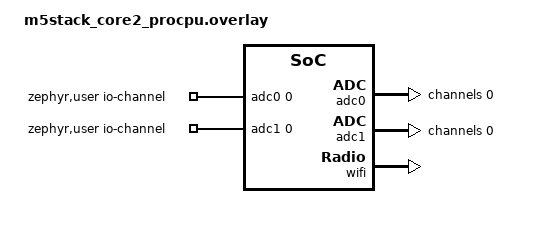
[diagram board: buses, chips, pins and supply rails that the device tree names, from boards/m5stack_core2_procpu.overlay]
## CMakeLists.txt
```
# SPDX-License-Identifier: Apache-2.0
cmake_minimum_required(VERSION 3.20.0)

set(BOARD m5stack_core2/esp32/procpu)
set(CONF_FILE prj.conf overlay-wifi.conf)

find_package(Zephyr REQUIRED HINTS $ENV{ZEPHYR_BASE})
project(weather_station)

target_include_directories(app PRIVATE include)

target_sources(app PRIVATE 
    src/wifi.c
    src/sockets.c
    src/weather_station.c
    src/main.c
)
target_sources_ifdef(CONFIG_WIFI app PRIVATE src/wifi.c)

set(gen_dir ${ZEPHYR_BINARY_DIR}/include/generated/)

generate_inc_file_for_target(
    app
    src/globalsign_r1.der
    ${gen_dir}/globalsign_r1.der.inc
    )
```

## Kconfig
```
#  Copyright (c) 2020 Gerson Fernando Budke <nandojve@gmail.com>
#  SPDX-License-Identifier: Apache-2.0

mainmenu "CSSE4011 Weather Station HTTP Client Configuration"

menu "Weather Station HTTP Client Configuration"

config HTTP_WIFI_SSID
	string "WIFI SSID - Network name"
	default "my_network"

config HTTP_WIFI_PSK
	string "WIFI PSK - Network password key"
	default "secret_passwd"

endmenu

source "Kconfig.zephyr"
```

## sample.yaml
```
sample:
  name: ADC devicetree driver sample
tests:
  sample.drivers.adc.adc_dt:
    tags:
      - adc
    depends_on: adc
    platform_allow:
      - m5stack_core2/esp32/procpu
    harness: console
    timeout: 10
    harness_config:
      type: multi_line
      regex:
        - "ADC reading\\[\\d+\\]:"
        - "- .+, channel \\d+: -?\\d+"
```

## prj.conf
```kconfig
CONFIG_ESP32_USE_UNSUPPORTED_REVISION=y
# ADC
CONFIG_ADC=y
CONFIG_SHELL=y
CONFIG_GPIO=y
CONFIG_GPIO_ESP32=y

CONFIG_CBPRINTF_FP_SUPPORT=y

# App stack
CONFIG_MAIN_STACK_SIZE=4096

### WiFi Connectivity ###
# C Library
# Default use minimal libc and with COMMON_LIBC_MALLOC_ARENA_SIZE defining
# HEAP size (512 bytes) are enough to run DNS.
CONFIG_COMMON_LIBC_MALLOC_ARENA_SIZE=4096

CONFIG_POSIX_API=y

# Networking config
CONFIG_NETWORKING=y
CONFIG_NET_IPV4=y
CONFIG_NET_IPV6=n
CONFIG_NET_TCP=y
CONFIG_NET_SHELL=y

# Sockets
CONFIG_NET_SOCKETS=y
CONFIG_ZVFS_POLL_MAX=4

# Network driver config
CONFIG_TEST_RANDOM_GENERATOR=y

# Network address config
CONFIG_NET_CONFIG_SETTINGS=y
CONFIG_NET_CONFIG_NEED_IPV4=y
CONFIG_NET_DHCPV4=y

# Resolver
CONFIG_DNS_RESOLVER=y

# HTTP
CONFIG_HTTP_CLIENT=y

# Network debug config
CONFIG_LOG=y
CONFIG_NET_LOG=y
CONFIG_NET_SOCKETS_LOG_LEVEL_DBG=n
CONFIG_NET_HTTP_LOG_LEVEL_DBG=n

# ESP-Specific Configs
CONFIG_WIFI_ESP32=y
CONFIG_NET_L2_ETHERNET=y
```

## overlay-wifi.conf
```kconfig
CONFIG_WIFI=y
CONFIG_HTTP_WIFI_SSID="OPPO Reno12 F 5G"
CONFIG_HTTP_WIFI_PSK="12345678"
CONFIG_NET_SOCKETS_SOCKOPT_TLS=n
CONFIG_NET_SOCKETS=y
CONFIG_MBEDTLS=y
```

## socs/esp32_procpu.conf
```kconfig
CONFIG_WIFI=y

CONFIG_NETWORKING=y
CONFIG_NET_L2_ETHERNET=y

CONFIG_NET_IPV6=n
CONFIG_NET_IPV4=y
CONFIG_NET_DHCPV4=y
CONFIG_ESP32_WIFI_STA_AUTO_DHCPV4=y

CONFIG_NET_LOG=y

CONFIG_HTTP_CLIENT=y
# CONFIG_HTTP_SERVER is not set
```

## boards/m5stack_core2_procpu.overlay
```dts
/ {
	zephyr,user {
		io-channels =
			<&adc0 0>,
			<&adc1 0>;
	};
};

&adc0 {
	status = "okay";
	#address-cells = <1>;
	#size-cells = <0>;

	channel@0 {
		reg = <0>;
		zephyr,gain = "ADC_GAIN_1_4";
		zephyr,reference = "ADC_REF_INTERNAL";
		zephyr,acquisition-time = <ADC_ACQ_TIME_DEFAULT>;
		zephyr,resolution = <12>;
	};
};

&adc1 {
	status = "okay";
	#address-cells = <1>;
	#size-cells = <0>;

	channel@0 {
		reg = <0>;
		zephyr,gain = "ADC_GAIN_1_4";
		zephyr,reference = "ADC_REF_INTERNAL";
		zephyr,acquisition-time = <ADC_ACQ_TIME_DEFAULT>;
		zephyr,resolution = <12>;
	};
};

&gpio0 {
    status = "okay";
};

&wifi {
	status = "okay";
};
```

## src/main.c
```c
/**
 * @file main.c
 * @brief HTTP Client demo application for weather station.
 *
 * This application collects data from a weather station, and sends it to 
 * csse4011-iot.uqcloud.net via an HTTP client. It logs HTTP responses and sensor data.
 */
#include <zephyr/logging/log.h>
#include <zephyr/kernel.h>
#include <zephyr/device.h>
#include <zephyr/drivers/gpio.h>
#include <zephyr/devicetree.h>
#include <zephyr/shell/shell.h>
#include <zephyr/sys/printk.h>
#include <zephyr/net/socket.h>
#include <zephyr/net/http/client.h>
#include <zephyr/random/random.h>
#include <stdio.h>

LOG_MODULE_REGISTER(main);

#include "wifi.h"
#include "sockets.h"
#include "weather_station.h"

#define GPIO_0   DT_NODELABEL(gpio0)
#define GPIO_PIN 27

/* Get device instances */
const struct device *gpio_dev = DEVICE_DT_GET(GPIO_0);
const struct device *adc_dev = DEVICE_DT_GET(DT_NODELABEL(adc0));

/* Global weather station instance */
WeatherStation ws;


/**
 * @brief Cycle Executive.
 *
 * Initializes the ADC and weather station, connects to Wi-Fi, and enters the main loop,
 * periodically collecting sensor data and transmitting it to csse4011-iot.uqcloud.net server.
 *
 * @return Always returns 0.
 */
int main(void)
{
    printk("Starting program\n");

    /* Initialize WiFi and weather station */
	wifi_connect();
    weather_station_init(&ws, adc_dev, gpio_dev, GPIO_PIN);
    LOG_INF("Weather station initialised\n");

    /* Main loop */
    while (1) {
        float wind_speed = weather_station_get_wind_speed(&ws);
        float wind_direction = weather_station_get_wind_direction(&ws);
        printk("Wind Speed: %f, Wind Direction: %f\n", (double)wind_speed, (double)wind_direction);
        if (http_get_dynamic(wind_speed, wind_direction) < 0) {
            LOG_INF("Error sending GET request.");
        }

        k_msleep(1000);
    }
    return 0;
}
```

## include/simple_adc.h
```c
#ifndef __SIMPLE_ADC_H__
#define __SIMPLE_ADC_H__

#include <stdbool.h>
#include <stdint.h>


/**
 * @brief Initializes the ADC channel.
 *
 * This function configures the ADC channel specified in the device tree overlay.
 * It first checks whether the ADC controller device is ready, and then sets up the ADC channel.
 *
 * @return 0 on success, or a negative error code if initialization fails.
 */
int adc_channel_initialise();

/**
 * @brief Reads the ADC channel and converts the raw value to millivolts.
 *
 * This function performs an ADC read operation on the specified channel.
 * It stores the raw ADC value, interprets it (as a signed value if using differential mode),
 * and converts it into millivolts. The resulting value is stored in the location provided.
 *
 * @param[out] out_val_mv Pointer to an integer where the resulting millivolt value will be stored.
 *
 * @return true if the read and conversion are successful, false otherwise.
 */
bool adc_channel_read_millivolt(int32_t *out_val_mv);

#endif
```

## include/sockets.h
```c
/*
 * Copyright (c) 2020 Gerson Fernando Budke <nandojve@gmail.com>
 *
 * SPDX-License-Identifier: Apache-2.0
 */
 
/**
 * @brief Sends an HTTP GET request with dynamic URL parameters.
 *
 * Constructs a URL using the given wind speed and wind direction, resolves the server address,
 * establishes a connection (with TLS if enabled), sends the HTTP GET request, and then closes the connection.
 *
 * @param wind_speed    The measured wind speed.
 * @param wind_direction The measured wind direction.
 *
 * @return int Returns 0 on success or a negative error code on failure.
 */
int http_get_dynamic(float wind_speed, float wind_direction);
```

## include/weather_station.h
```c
/**
 * @file weather_station.h
 * @brief Weather station sensor driver.
 *
 * Adapted from https://github.com/sparkfun/SparkFun_Weather_Meter_Kit_Arduino_Library
 */

#ifndef SFE_WEATHER_METER_KIT_H
#define SFE_WEATHER_METER_KIT_H

#include <zephyr/drivers/adc.h>
#include <zephyr/drivers/gpio.h>
#include <stdint.h>

#ifdef __cplusplus
extern "C" {
#endif

/*----------------------------------------------------------------------------
 * Macros and Constants
 *----------------------------------------------------------------------------
 * Define the number of wind vane positions, ADC resolution, and conversion
 * constants. Adjust these values as needed.
 */
#define WMK_NUM_ANGLES                 16

#define WMK_ANGLE_0_0                  0
#define WMK_ANGLE_22_5                 1
#define WMK_ANGLE_45_0                 2
#define WMK_ANGLE_67_5                 3
#define WMK_ANGLE_90_0                 4
#define WMK_ANGLE_112_5                5
#define WMK_ANGLE_135_0                6
#define WMK_ANGLE_157_5                7
#define WMK_ANGLE_180_0                8
#define WMK_ANGLE_202_5                9
#define WMK_ANGLE_225_0                10
#define WMK_ANGLE_247_5                11
#define WMK_ANGLE_270_0                12
#define WMK_ANGLE_292_5                13
#define WMK_ANGLE_315_0                14
#define WMK_ANGLE_337_5                15

#define SFE_WMK_ADC_RESOLUTION         10   // Example: 10-bit ADC resolution
#define SFE_WIND_VANE_DEGREES_PER_INDEX 22.5f

/*----------------------------------------------------------------------------
 * Data Structures
 *----------------------------------------------------------------------------
 */

/**
 * @brief Calibration parameters for wind measurements.
 *
 * Contains ADC calibration values for the wind vane and measurement
 * parameters for computing wind speed.
 */
typedef struct {
    uint16_t vaneADCValues[WMK_NUM_ANGLES];
    float    kphPerCountPerSec;
    uint32_t windSpeedMeasurementPeriodMillis;
} SFEWeatherMeterKitCalibrationParams;

/**
 * @brief Main structure for the Weather Meter Kit.
 *
 * Holds calibration parameters, measurement counters, timing information,
 * and device/pin configuration for wind speed and wind direction.
 */
typedef struct {
    SFEWeatherMeterKitCalibrationParams calibrationParams;
    uint32_t windCountsPrevious;
    uint32_t windCounts;
    uint32_t lastWindSpeedMillis;
    const struct device *adc_dev;          /**< ADC device for wind direction sensor */
    int                   wind_dir_adc_channel; /**< ADC channel for wind direction */
    const struct device *gpio_dev;         /**< GPIO device for wind speed sensor */
    int                   wind_speed_pin;   /**< GPIO pin for wind speed sensor */
    struct gpio_callback  wind_speed_cb;    /**< GPIO callback structure */
} SFEWeatherMeterKit;

/*----------------------------------------------------------------------------
 * Public Function Prototypes
 *----------------------------------------------------------------------------
 */

/**
 * @brief Initialize the Weather Meter Kit structure.
 *
 * Configures device pointers, ADC channel, calibration parameters, and resets
 * counters/timers.
 *
 * @param kit Pointer to a SFEWeatherMeterKit structure.
 * @param adc_dev Pointer to the ADC device (obtained via device_get_binding()).
 * @param wind_dir_adc_channel ADC channel number for the wind direction sensor.
 * @param gpio_dev Pointer to the GPIO device for the wind speed sensor.
 * @param wind_speed_pin GPIO pin number for the wind speed sensor.
 */
void SFEWeatherMeterKit_init(SFEWeatherMeterKit *kit,
                             const struct device *adc_dev,
                             int wind_dir_adc_channel,
                             const struct device *gpio_dev,
                             int wind_speed_pin);

/**
 * @brief Begin sensor operation.
 *
 * Configures the wind speed GPIO pin (with pull-up) and sets up the interrupt
 * callback.
 *
 * @param kit Pointer to a SFEWeatherMeterKit structure.
 * @return 0 on success, negative error code on failure.
 */
int SFEWeatherMeterKit_begin(SFEWeatherMeterKit *kit);

/**
 * @brief Get the current calibration parameters.
 *
 * @param kit Pointer to a SFEWeatherMeterKit structure.
 * @return A SFEWeatherMeterKitCalibrationParams structure.
 */
SFEWeatherMeterKitCalibrationParams SFEWeatherMeterKit_getCalibrationParams(SFEWeatherMeterKit *kit);

/**
 * @brief Set new calibration parameters.
 *
 * @param kit Pointer to a SFEWeatherMeterKit structure.
 * @param params New calibration parameters.
 */
void SFEWeatherMeterKit_setCalibrationParams(SFEWeatherMeterKit *kit,
                                             SFEWeatherMeterKitCalibrationParams params);

/**
 * @brief Adjust the ADC resolution of the calibration values.
 *
 * @param kit Pointer to a SFEWeatherMeterKit structure.
 * @param resolutionBits The desired ADC resolution (in bits).
 */
void SFEWeatherMeterKit_setADCResolutionBits(SFEWeatherMeterKit *kit, uint8_t resolutionBits);

/**
 * @brief Get the wind direction in degrees.
 *
 * Reads the ADC value from the wind vane, compares it to calibration values,
 * and returns the closest matching direction.
 *
 * @param kit Pointer to a SFEWeatherMeterKit structure.
 * @return Wind direction in degrees.
 */
float SFEWeatherMeterKit_getWindDirection(SFEWeatherMeterKit *kit);

/**
 * @brief Get the measured wind speed in kilometers per hour.
 *
 * Computes wind speed based on the counts recorded during the last measurement window.
 *
 * @param kit Pointer to a SFEWeatherMeterKit structure.
 * @return Wind speed in kph.
 */
float SFEWeatherMeterKit_getWindSpeed(SFEWeatherMeterKit *kit);

/**
 * @brief Get the number of wind speed counts.
 *
 * Returns the current count of wind speed pulses in the current measurement window.
 *
 * @param kit Pointer to a SFEWeatherMeterKit structure.
 * @return Wind speed counts.
 */
uint32_t SFEWeatherMeterKit_getWindSpeedCounts(SFEWeatherMeterKit *kit);

/**
 * @brief Reset the wind speed measurement filter.
 *
 * Resets wind speed counters and timer to start a new measurement window.
 *
 * @param kit Pointer to a SFEWeatherMeterKit structure.
 */
void SFEWeatherMeterKit_resetWindSpeedFilter(SFEWeatherMeterKit *kit);

/**
 * @brief Generic wrapper for the weather station.
 *
 * This structure encapsulates your SFEWeatherMeterKit instance.
 */
 typedef struct {
    SFEWeatherMeterKit kit;
} WeatherStation;

/**
 * @brief Initialize the weather station.
 *
 * @param ws Pointer to the WeatherStation instance.
 * @param adc_dev ADC device pointer.
 * @param gpio_dev GPIO device pointer.
 * @param gpio_pin The GPIO pin number used.
 */
void weather_station_init(WeatherStation *ws,
                          const struct device *adc_dev,
                          const struct device *gpio_dev,
                          uint32_t gpio_pin);

/**
 * @brief Get the current wind speed.
 *
 * @param ws Pointer to the WeatherStation instance.
 * @return Wind speed as a float.
 */
float weather_station_get_wind_speed(WeatherStation *ws);

/**
 * @brief Get the current wind direction.
 *
 * @param ws Pointer to the WeatherStation instance.
 * @return Wind direction as a float.
 */
float weather_station_get_wind_direction(WeatherStation *ws);

#ifdef __cplusplus
}
#endif

#endif /* SFE_WEATHER_METER_KIT_H */
```

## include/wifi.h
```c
/*
 * Copyright (c) 2020 Gerson Fernando Budke <nandojve@gmail.com>
 *
 * SPDX-License-Identifier: Apache-2.0
 */

#if defined(CONFIG_WIFI)
/**
 * @brief Connect to a WiFi network.
 *
 * Initiates a connection to a WiFi network using the configuration parameters (SSID and PSK)
 * defined in the build configuration.
 */
void wifi_connect(void);

#else
#define wifi_connect()
#endif
```

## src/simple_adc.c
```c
/*
 * Copyright (c) 2020 Libre Solar Technologies GmbH
 *
 * SPDX-License-Identifier: Apache-2.0
 */

#include <inttypes.h>
#include <stddef.h>
#include <stdint.h>

#include <zephyr/device.h>
#include <zephyr/devicetree.h>
#include <zephyr/drivers/adc.h>
#include <zephyr/kernel.h>
#include <zephyr/sys/printk.h>
#include <zephyr/sys/util.h>

#if !DT_NODE_EXISTS(DT_PATH(zephyr_user)) || !DT_NODE_HAS_PROP(DT_PATH(zephyr_user), io_channels)
#error "No suitable devicetree overlay specified"
#endif

/** 
 * ADC channel specification retrieved from the device tree.
 */
static const struct adc_dt_spec adc_channel0 = ADC_DT_SPEC_GET(DT_PATH(zephyr_user));

/**
 * @brief Initializes the ADC channel.
 *
 * This function configures the ADC channel specified in the device tree overlay.
 * It first checks whether the ADC controller device is ready, and then sets up the ADC channel.
 *
 * @return 0 on success, or a negative error code if initialization fails.
 */
int adc_channel_initialise()
{
	/* Configure channels individually prior to sampling. */
	if (!adc_is_ready_dt(&adc_channel0)) {
		printk("ADC controller device %s not ready\n", adc_channel0.dev->name);
		return -ENODEV;
	}

	int err = adc_channel_setup_dt(&adc_channel0);
	if (err < 0) {
		printk("Could not setup channel (%d)\n", err);
		return 0;
	}
	return err;
}

/**
 * @brief Reads the ADC channel and converts the raw value to millivolts.
 *
 * This function performs an ADC read operation on the specified channel.
 * It stores the raw ADC value, interprets it (as a signed value if using differential mode),
 * and converts it into millivolts. The resulting value is stored in the location provided.
 *
 * @param[out] out_val_mv Pointer to an integer where the resulting millivolt value will be stored.
 *
 * @return true if the read and conversion are successful, false otherwise.
 */
bool adc_channel_read_millivolt(int32_t *out_val_mv)
{

	uint16_t buf;
	struct adc_sequence sequence = {
		.buffer = &buf,
		/* buffer size in bytes, not number of samples */
		.buffer_size = sizeof(buf),
	};

	(void)adc_sequence_init_dt(&adc_channel0, &sequence);

	int err = adc_read_dt(&adc_channel0, &sequence);
	if (err < 0) {
		printk("Could not read (%d)\n", err);
		return false;
	}

	/*
	 * If using differential mode, the 16 bit value
	 * in the ADC sample buffer should be a signed 2's
	 * complement value.
	 */
	if (adc_channel0.channel_cfg.differential) {
		*out_val_mv = (int32_t)((int16_t)buf);
	} else {
		*out_val_mv = (int32_t)buf;
	}

	err = adc_raw_to_millivolts_dt(&adc_channel0, out_val_mv);
	/* conversion to mV may not be supported, skip if not */
	if (err < 0) {
		return false;
	}

	return true;
}
```

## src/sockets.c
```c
/*
 * Copyright (c) 2020 Gerson Fernando Budke <nandojve@gmail.com>
 *
 * SPDX-License-Identifier: Apache-2.0
 */

 #include <zephyr/logging/log.h>
 #include <zephyr/net/net_ip.h>
 #include <zephyr/net/socket.h>
 #include <zephyr/net/socketutils.h>
 #include <zephyr/net/dns_resolve.h>
 #include <zephyr/net/tls_credentials.h>
 #include <zephyr/net/http/client.h>
 
 #if defined(CONFIG_NET_SOCKETS_SOCKOPT_TLS)
 #include <zephyr/net/tls_credentials.h>
 #include "ca_certificate.h"
 #endif

 #include "sockets.h"
 
#define HTTP_HOST "csse4011-iot.uqcloud.net"
#define HTTP_PATH "/"
#if defined(CONFIG_NET_SOCKETS_SOCKOPT_TLS)
#define HTTP_PORT "443"
#else
#define HTTP_PORT "80"
#endif

/**
 * @brief Sends an HTTP GET request with a dynamic URL.
 *
 * This function constructs a dynamic URL using the provided wind speed and wind direction values,
 * resolves the server hostname, and establishes a connection (with TLS if configured). It then
 * sends an HTTP GET request to the server with the URL parameters and closes the socket.
 *
 * @param wind_speed    The measured wind speed.
 * @param wind_direction The measured wind direction.
 *
 * @return int Returns 0 on success, or a negative error code on failure.
 */
int http_get_dynamic(float wind_speed, float wind_direction)
{
    int ret;
    struct addrinfo hints = {0}, *res = NULL;
    int sock;

    /* Build the dynamic URL */
    char dynamic_path[100];
    ret = snprintk(dynamic_path, sizeof(dynamic_path),
                   "/add.php?stationid=4011&speed=%.2f&direction=%.2f",
                   (double)wind_speed, (double)wind_direction);
    if (ret <= 0 || ret >= sizeof(dynamic_path)) {
        printk("Error: Could not build dynamic URL.\n");
        return -1;
    }

    printk("Sending GET request to https://%s%s\n", HTTP_HOST, dynamic_path);

    hints.ai_family = AF_INET;
    hints.ai_socktype = SOCK_STREAM;
    ret = getaddrinfo(HTTP_HOST, HTTP_PORT, &hints, &res);
    if (ret != 0) {
        printk("Error: getaddrinfo() failed (%d)\n", ret);
        return -1;
    }

#if defined(CONFIG_NET_SOCKETS_SOCKOPT_TLS)
    sock = socket(res->ai_family, res->ai_socktype, IPPROTO_TLS_1_2);
#else
    sock = socket(res->ai_family, res->ai_socktype, res->ai_protocol);
#endif
    if (sock < 0) {
        printk("Error: socket() failed (%d)\n", sock);
        freeaddrinfo(res);
        return -1;
    }

#if defined(CONFIG_NET_SOCKETS_SOCKOPT_TLS)
    {
        sec_tag_t sec_tag_opt[] = { CA_CERTIFICATE_TAG };
        ret = setsockopt(sock, SOL_TLS, TLS_SEC_TAG_LIST, sec_tag_opt, sizeof(sec_tag_opt));
        if (ret < 0) {
            printk("Error: setsockopt TLS_SEC_TAG_LIST: %d\n", ret);
            close(sock);
            freeaddrinfo(res);
            return ret;
        }
        ret = setsockopt(sock, SOL_TLS, TLS_HOSTNAME, HTTP_HOST, strlen(HTTP_HOST));
        if (ret < 0) {
            printk("Error: setsockopt TLS_HOSTNAME: %d\n", ret);
            close(sock);
            freeaddrinfo(res);
            return ret;
        }
    }
#endif

    ret = connect(sock, res->ai_addr, res->ai_addrlen);
    if (ret < 0) {
        printk("Error: connect() failed (%d)\n", ret);
        close(sock);
        freeaddrinfo(res);
        return ret;
    }
    freeaddrinfo(res);

    /* Build the HTTP GET request with the dynamic URL */
    char req_buf[512];
    int req_len = snprintk(req_buf, sizeof(req_buf),
                           "GET %s HTTP/1.1\r\n"
                           "Host: %s\r\n"
                           "Connection: close\r\n"
                           "\r\n",
                           dynamic_path, HTTP_HOST);
    if (req_len <= 0 || req_len >= sizeof(req_buf)) {
        printk("Error: Request buffer too small or snprintk error\n");
        close(sock);
        return -1;
    }

    ret = send(sock, req_buf, req_len, 0);
    if (ret < 0) {
        printk("Error: send() failed (%d)\n", ret);
        close(sock);
        return ret;
    }

    /* Receive and print the server response */
    // adds latency, by-pass this for now.
    // char response[512];
    // while (1) {
    //     ret = recv(sock, response, sizeof(response) - 1, 0);
    //     if (ret < 0) {
    //         printk("Error: recv() failed (%d)\n", ret);
    //         break;
    //     }
    //     if (ret == 0) {
    //         /* Server closed connection */
    //         break;
    //     }
    //     response[ret] = '\0';
    //     printk("%s", response);
    // }
    close(sock);
    printk("\nSocket closed.\n");
    return 0;
}
```

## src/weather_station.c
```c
/**
 * @file weather_station.c
 * @brief Weather station sensor driver.
 *
 * Adapted from github.com/sparkfun/SparkFun_Weather_Meter_Kit_Arduino_Library
 */

#include <weather_station.h>
#include <zephyr/device.h>
#include <zephyr/sys/printk.h>
#include <stdint.h>
#include <string.h>
#include <stdlib.h>

/*----------------------------------------------------------------------------
 * Macros and Calibration Constants
 *----------------------------------------------------------------------------
 * Define the number of wind vane positions and the calibration ADC values.
 * Adjust these values to suit your hardware and calibration.
 */
#define SFE_WMK_ADC_ANGLE_0_0   444
#define SFE_WMK_ADC_ANGLE_22_5  231
#define SFE_WMK_ADC_ANGLE_45_0  263
#define SFE_WMK_ADC_ANGLE_67_5  52
#define SFE_WMK_ADC_ANGLE_90_0  57
#define SFE_WMK_ADC_ANGLE_112_5 41
#define SFE_WMK_ADC_ANGLE_135_0 107
#define SFE_WMK_ADC_ANGLE_157_5 75
#define SFE_WMK_ADC_ANGLE_180_0 164
#define SFE_WMK_ADC_ANGLE_202_5 142
#define SFE_WMK_ADC_ANGLE_225_0 358
#define SFE_WMK_ADC_ANGLE_247_5 340
#define SFE_WMK_ADC_ANGLE_270_0 531
#define SFE_WMK_ADC_ANGLE_292_5 466
#define SFE_WMK_ADC_ANGLE_315_0 500
#define SFE_WMK_ADC_ANGLE_337_5 398 

#define SFE_WMK_ADC_RESOLUTION          10  // 10-bit ADC resolution
#define SFE_WIND_VANE_DEGREES_PER_INDEX 22.5f

/*----------------------------------------------------------------------------
 * Global Instance Pointer for Interrupt Context
 *----------------------------------------------------------------------------
 * For simplicity (and because typical ISRs cannot have a context pointer),
 * we use a global pointer to the one active kit instance.
 */
static SFEWeatherMeterKit *kit_instance = NULL;

/*----------------------------------------------------------------------------
 * Forward Declarations for Callbacks
 *----------------------------------------------------------------------------
 */
static void wind_speed_callback(const struct device *dev,
                                struct gpio_callback *cb,
                                uint32_t pins);

/*----------------------------------------------------------------------------
 * ADC Channel Configuration Helper
 *----------------------------------------------------------------------------
 * Configures the ADC channel used by the wind direction sensor.
 */
static int configure_adc_channel(SFEWeatherMeterKit *kit)
{
    struct adc_channel_cfg channel_cfg = {
        .gain             = ADC_GAIN_1_4,
        .reference        = ADC_REF_INTERNAL,
        .acquisition_time = ADC_ACQ_TIME_DEFAULT,
        .channel_id       = kit->wind_dir_adc_channel,
        .differential     = 0,
#if defined(CONFIG_ADC_CONFIGURABLE_INPUTS)
        .input_positive   = kit->wind_dir_adc_channel,
#endif
    };
    return adc_channel_setup(kit->adc_dev, &channel_cfg);
}

/*----------------------------------------------------------------------------
 * Initialization Function
 *----------------------------------------------------------------------------
 * Initializes the kit structure, sets calibration values, configures the ADC channel,
 * and stores the GPIO and ADC devices and pin numbers.
 *
 * Parameters:
 *  - kit: Pointer to an SFEWeatherMeterKit structure.
 *  - adc_dev: Pointer to the ADC device (e.g. obtained via device_get_binding()).
 *  - wind_dir_adc_channel: The ADC channel number for the wind direction sensor.
 *  - gpio_dev: Pointer to the GPIO device used for the wind speed sensor.
 *  - wind_speed_pin: The GPIO pin number for the wind speed sensor.
 */
void SFEWeatherMeterKit_init(SFEWeatherMeterKit *kit,
                             const struct device *adc_dev,
                             int wind_dir_adc_channel,
                             const struct device *gpio_dev,
                             int wind_speed_pin)
{
    /* Save device pointers and pin numbers */
    kit->adc_dev = adc_dev;
    kit->wind_dir_adc_channel = wind_dir_adc_channel;
    kit->gpio_dev = gpio_dev;
    kit->wind_speed_pin = wind_speed_pin;

    /* Configure the ADC channel */
    if (configure_adc_channel(kit) < 0) {
        printk("Failed to configure ADC channel\n");
    }

    /* Set calibration ADC values for the wind vane */
    kit->calibrationParams.vaneADCValues[WMK_ANGLE_0_0]   = SFE_WMK_ADC_ANGLE_0_0;
    kit->calibrationParams.vaneADCValues[WMK_ANGLE_22_5]  = SFE_WMK_ADC_ANGLE_22_5;
    kit->calibrationParams.vaneADCValues[WMK_ANGLE_45_0]  = SFE_WMK_ADC_ANGLE_45_0;
    kit->calibrationParams.vaneADCValues[WMK_ANGLE_67_5]  = SFE_WMK_ADC_ANGLE_67_5;
    kit->calibrationParams.vaneADCValues[WMK_ANGLE_90_0]  = SFE_WMK_ADC_ANGLE_90_0;
    kit->calibrationParams.vaneADCValues[WMK_ANGLE_112_5] = SFE_WMK_ADC_ANGLE_112_5;
    kit->calibrationParams.vaneADCValues[WMK_ANGLE_135_0] = SFE_WMK_ADC_ANGLE_135_0;
    kit->calibrationParams.vaneADCValues[WMK_ANGLE_157_5] = SFE_WMK_ADC_ANGLE_157_5;
    kit->calibrationParams.vaneADCValues[WMK_ANGLE_180_0] = SFE_WMK_ADC_ANGLE_180_0;
    kit->calibrationParams.vaneADCValues[WMK_ANGLE_202_5] = SFE_WMK_ADC_ANGLE_202_5;
    kit->calibrationParams.vaneADCValues[WMK_ANGLE_225_0] = SFE_WMK_ADC_ANGLE_225_0;
    kit->calibrationParams.vaneADCValues[WMK_ANGLE_247_5] = SFE_WMK_ADC_ANGLE_247_5;
    kit->calibrationParams.vaneADCValues[WMK_ANGLE_270_0] = SFE_WMK_ADC_ANGLE_270_0;
    kit->calibrationParams.vaneADCValues[WMK_ANGLE_292_5] = SFE_WMK_ADC_ANGLE_292_5;
    kit->calibrationParams.vaneADCValues[WMK_ANGLE_315_0] = SFE_WMK_ADC_ANGLE_315_0;
    kit->calibrationParams.vaneADCValues[WMK_ANGLE_337_5] = SFE_WMK_ADC_ANGLE_337_5;

    /* Set other calibration parameters */
    kit->calibrationParams.kphPerCountPerSec = 2.4f;
    kit->calibrationParams.windSpeedMeasurementPeriodMillis = 1000;

    /* Reset counters and timers using Zephyr’s uptime (milliseconds) */
    kit->windCountsPrevious = 0;
    kit->windCounts = 0;
    kit->lastWindSpeedMillis = k_uptime_get_32();

    /* Save this instance for use in the interrupt callback */
    kit_instance = kit;
}

/*----------------------------------------------------------------------------
 * Begin Function
 *----------------------------------------------------------------------------
 * Configures the GPIO pin for the wind speed sensor and attaches an interrupt
 * callback.
 */
int SFEWeatherMeterKit_begin(SFEWeatherMeterKit *kit)
{
    int ret;

    /* Configure wind speed pin as input with pull-up */
    ret = gpio_pin_configure(kit->gpio_dev, kit->wind_speed_pin, GPIO_INPUT | GPIO_PULL_UP);
    if (ret < 0) {
        printk("Error configuring wind speed pin\n");
        return ret;
    }

    /* Initialize and add the wind speed callback */
    gpio_init_callback(&kit->wind_speed_cb, wind_speed_callback, BIT(kit->wind_speed_pin));
    ret = gpio_add_callback(kit->gpio_dev, &kit->wind_speed_cb);
    if (ret < 0) {
        printk("Error adding wind speed callback\n");
        return ret;
    }

    /* Configure interrupt for wind speed sensor on both edges */
    ret = gpio_pin_interrupt_configure(kit->gpio_dev, kit->wind_speed_pin, GPIO_INT_EDGE_BOTH);
    if (ret < 0) {
        printk("Error configuring wind speed interrupt\n");
        return ret;
    }

    return 0;
}

/*----------------------------------------------------------------------------
 * Calibration Parameter Accessor and ADC Resolution Adjustment
 *----------------------------------------------------------------------------
 */
SFEWeatherMeterKitCalibrationParams SFEWeatherMeterKit_getCalibrationParams(SFEWeatherMeterKit *kit)
{
    return kit->calibrationParams;
}

void SFEWeatherMeterKit_setCalibrationParams(SFEWeatherMeterKit *kit,
                                             SFEWeatherMeterKitCalibrationParams params)
{
    memcpy(&kit->calibrationParams, &params, sizeof(SFEWeatherMeterKitCalibrationParams));
}

void SFEWeatherMeterKit_setADCResolutionBits(SFEWeatherMeterKit *kit, uint8_t resolutionBits)
{
    for (uint8_t i = 0; i < WMK_NUM_ANGLES; i++) {
        int8_t bitShift = SFE_WMK_ADC_RESOLUTION - resolutionBits;
        if (bitShift > 0) {
            kit->calibrationParams.vaneADCValues[i] >>= bitShift;
        } else if (bitShift < 0) {
            kit->calibrationParams.vaneADCValues[i] <<= (-bitShift);
        }
    }
}

/*----------------------------------------------------------------------------
 * Wind Direction Measurement
 *----------------------------------------------------------------------------
 * Reads the wind direction sensor via the ADC, compares the reading against
 * calibration values, and returns the closest matching wind direction in degrees.
 */
float SFEWeatherMeterKit_getWindDirection(SFEWeatherMeterKit *kit)
{
    int32_t rawADC = 0;
    int16_t sample_buffer = 0;
    struct adc_sequence sequence = {
        .channels    = BIT(kit->wind_dir_adc_channel),
        .buffer      = &sample_buffer,
        .buffer_size = sizeof(sample_buffer),
        .resolution  = SFE_WMK_ADC_RESOLUTION,
    };

    if (adc_read(kit->adc_dev, &sequence) < 0) {
        printk("ADC read error\n");
        return -1.0f;
    }
    rawADC = (int32_t)sample_buffer;

    int16_t closestDifference = 10;
    uint8_t closestIndex = 0;
    for (uint8_t i = 0; i < WMK_NUM_ANGLES; i++) {
        int16_t diff = kit->calibrationParams.vaneADCValues[i] - rawADC;
        diff = abs(diff);
        if (diff < closestDifference) {
            closestDifference = diff;
            closestIndex = i;
        }
    }
    float direction = closestIndex * SFE_WIND_VANE_DEGREES_PER_INDEX;
    return direction;
}

/*----------------------------------------------------------------------------
 * Wind Speed Measurement Update
 *----------------------------------------------------------------------------
 * Uses a fixed measurement window to update the wind speed counters.
 */
static void updateWindSpeed(SFEWeatherMeterKit *kit)
{
    uint32_t tNow = k_uptime_get_32();
    uint32_t dt = tNow - kit->lastWindSpeedMillis;

    if (dt < kit->calibrationParams.windSpeedMeasurementPeriodMillis) {
        /* Still within the current measurement window */
    } else {
        if (dt > (kit->calibrationParams.windSpeedMeasurementPeriodMillis * 2)) {
            /* No pulses for over two periods: reset counters */
            kit->windCountsPrevious = 0;
            kit->windCounts = 0;
            kit->lastWindSpeedMillis = tNow;
        } else {
            /* End of the measurement window: store the count and reset */
            kit->windCountsPrevious = kit->windCounts;
            kit->windCounts = 0;
            kit->lastWindSpeedMillis += kit->calibrationParams.windSpeedMeasurementPeriodMillis;
        }
    }
}

/*----------------------------------------------------------------------------
 * Get Wind Speed
 *----------------------------------------------------------------------------
 * Computes the wind speed in kph based on the counts recorded during the last
 * measurement window.
 */
float SFEWeatherMeterKit_getWindSpeed(SFEWeatherMeterKit *kit)
{
    updateWindSpeed(kit);
    float windSpeed = ((float) kit->windCountsPrevious / kit->calibrationParams.windSpeedMeasurementPeriodMillis)
                      * 1000 * kit->calibrationParams.kphPerCountPerSec / 2;
    return windSpeed;
}

/*----------------------------------------------------------------------------
 * Additional Accessors and Reset Functions
 *----------------------------------------------------------------------------
 */
uint32_t SFEWeatherMeterKit_getWindSpeedCounts(SFEWeatherMeterKit *kit)
{
    return kit->windCounts;
}

void SFEWeatherMeterKit_resetWindSpeedFilter(SFEWeatherMeterKit *kit)
{
    kit->windCountsPrevious = 0;
    kit->windCounts = 0;
    kit->lastWindSpeedMillis = k_uptime_get_32();
}

float weather_station_get_wind_speed(WeatherStation *ws)
{
    return SFEWeatherMeterKit_getWindSpeed(&ws->kit);
}

float weather_station_get_wind_direction(WeatherStation *ws)
{
    return SFEWeatherMeterKit_getWindDirection(&ws->kit);
}

/*----------------------------------------------------------------------------
 * GPIO Interrupt Callback for Wind Speed Sensor
 *----------------------------------------------------------------------------
 */
static void wind_speed_callback(const struct device *dev,
                                struct gpio_callback *cb,
                                uint32_t pins)
{
    if (kit_instance != NULL) {
        updateWindSpeed(kit_instance);
        kit_instance->windCounts++;
    }
}

/*----------------------------------------------------------------------------
 * Helper Functions for Initializations
 *----------------------------------------------------------------------------
 */
void weather_station_init(WeatherStation *ws,
    const struct device *adc_dev,
    const struct device *gpio_dev,
    uint32_t gpio_pin)
{
    SFEWeatherMeterKit_init(&ws->kit, adc_dev, 0, gpio_dev, gpio_pin);
    SFEWeatherMeterKit_setADCResolutionBits(&ws->kit, 10);
    SFEWeatherMeterKit_begin(&ws->kit);
}
```

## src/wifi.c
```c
/*
 * Copyright (c) 2020 Gerson Fernando Budke <nandojve@gmail.com>
 *
 * SPDX-License-Identifier: Apache-2.0
 */

#include <zephyr/logging/log.h>
LOG_MODULE_REGISTER(wifi); 
#include <zephyr/net/wifi_mgmt.h>

static int connected;
static struct net_mgmt_event_callback wifi_shell_mgmt_cb;
 
/**
 * @brief Handle the result of a WiFi connection attempt.
 *
 * Processes the connection status received from the WiFi management event callback.
 *
 * @param cb Pointer to the net management event callback containing WiFi status information.
 */
static void handle_wifi_connect_result(struct net_mgmt_event_callback *cb)
{
    const struct wifi_status *status = (const struct wifi_status *)
                    cb->info;

    if (status->status) {
        LOG_ERR("Connection request failed (%d)", status->status);
    } else {
        LOG_INF("WIFI Connected");
        connected = 1;
    }
}
 
/**
 * @brief WiFi management event handler.
 *
 * Handles WiFi management events.
 *
 * @param cb Pointer to the net management event callback.
 * @param mgmt_event The management event identifier.
 * @param iface Pointer to the network interface associated with the event.
 */
static void wifi_mgmt_event_handler(struct net_mgmt_event_callback *cb,
                    uint32_t mgmt_event, struct net_if *iface)
{
    switch (mgmt_event) {
    case NET_EVENT_WIFI_CONNECT_RESULT:
        handle_wifi_connect_result(cb);
        break;
    default:
        break;
    }
}
 
/**
 * @brief Initiate a WiFi connection.
 *
 * Registers the WiFi management callback, configures connection parameters, 
 * and attempts to connect up to 10 times, waiting until a connection is established.
 */
void wifi_connect(void)
{
    int nr_tries = 10;
    int ret = 0;

    net_mgmt_init_event_callback(&wifi_shell_mgmt_cb,
                    wifi_mgmt_event_handler,
                    NET_EVENT_WIFI_CONNECT_RESULT);

    net_mgmt_add_event_callback(&wifi_shell_mgmt_cb);

    struct net_if *iface = net_if_get_default();
    static struct wifi_connect_req_params cnx_params = {
        .ssid = CONFIG_HTTP_WIFI_SSID,
        .ssid_length = 0,
        .psk = CONFIG_HTTP_WIFI_PSK,
        .psk_length = 0,
        .channel = 0,
        .security = WIFI_SECURITY_TYPE_PSK,
    };

    cnx_params.ssid_length = strlen(CONFIG_HTTP_WIFI_SSID);
    cnx_params.psk_length = strlen(CONFIG_HTTP_WIFI_PSK);

    connected = 0;

    LOG_INF("WIFI try connecting to %s...", CONFIG_HTTP_WIFI_SSID);

    /* Let's wait few seconds to allow wifi device be on-line */
    while (nr_tries-- > 0) {
        ret = net_mgmt(NET_REQUEST_WIFI_CONNECT, iface, &cnx_params,
                sizeof(struct wifi_connect_req_params));
        if (ret == 0) {
            break;
        }

        LOG_INF("Connect request failed %d. Waiting iface be up...", ret);
        k_msleep(500);
    }

    while (connected == 0) {
        k_msleep(100);
    }
}
```
